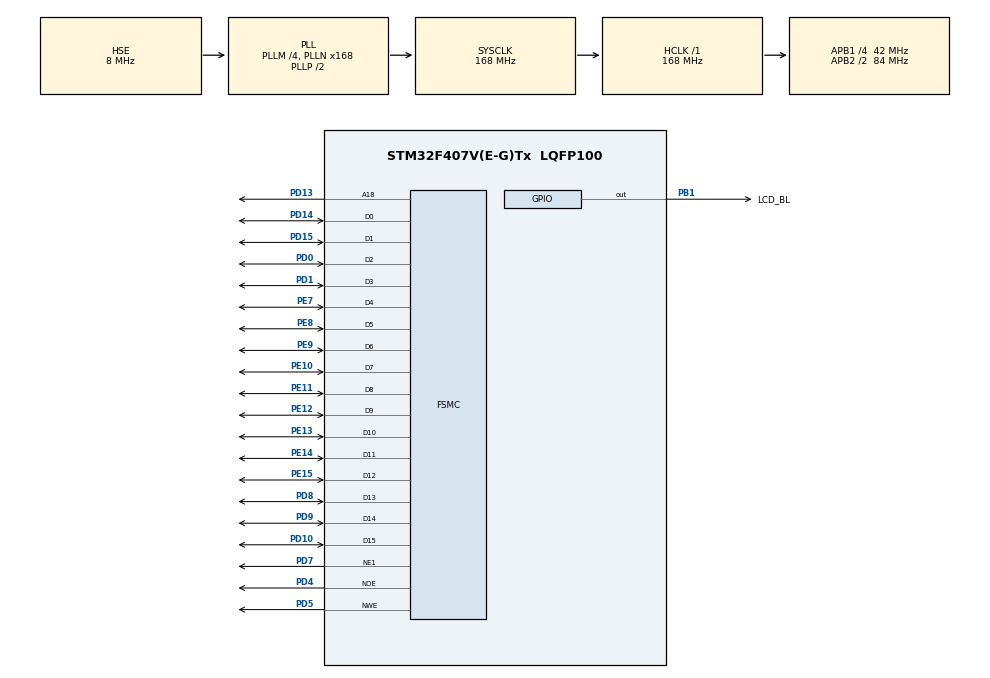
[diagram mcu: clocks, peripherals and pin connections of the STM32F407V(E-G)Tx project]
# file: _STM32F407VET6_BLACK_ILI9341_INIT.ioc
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FSMC.BusTurnAroundDuration1=0
FSMC.DataSetupTime1=60
FSMC.ExtendedAddressSetupTime1=9
FSMC.ExtendedBusTurnAroundDuration1=0
FSMC.ExtendedDataSetupTime1=8
FSMC.ExtendedMode1=FSMC_EXTENDED_MODE_ENABLE
Mcu.Family=STM32F4
Mcu.Name=STM32F407V(E-G)Tx
Mcu.Package=LQFP100
NVIC.PriorityGroup=NVIC_PRIORITYGROUP_4
PA13.Mode=Serial_Wire
PA13.Signal=SYS_JTMS-SWDIO
PA14.Mode=Serial_Wire
PA14.Signal=SYS_JTCK-SWCLK
PB1.GPIO_Label=LCD_BL
PB1.Signal=GPIO_Output
PD0.Mode=16b-d1
PD0.Signal=FSMC_D2
PD1.Mode=16b-d1
PD1.Signal=FSMC_D3
PD10.Mode=16b-d1
PD10.Signal=FSMC_D15
PD13.Mode=A18_1
PD13.Signal=FSMC_A18
PD14.Mode=16b-d1
PD14.Signal=FSMC_D0
PD15.Mode=16b-d1
PD15.Signal=FSMC_D1
PD4.Mode=Lcd1
PD4.Signal=FSMC_NOE
PD5.Mode=Lcd1
PD5.Signal=FSMC_NWE
PD7.Mode=NorPsramChipSelect1_1
PD7.Signal=FSMC_NE1
PD8.Mode=16b-d1
PD8.Signal=FSMC_D13
PD9.Mode=16b-d1
PD9.Signal=FSMC_D14
PE10.Mode=16b-d1
PE10.Signal=FSMC_D7
PE11.Mode=16b-d1
PE11.Signal=FSMC_D8
PE12.Mode=16b-d1
PE12.Signal=FSMC_D9
PE13.Mode=16b-d1
PE13.Signal=FSMC_D10
PE14.Mode=16b-d1
PE14.Signal=FSMC_D11
PE15.Mode=16b-d1
PE15.Signal=FSMC_D12
PE7.Mode=16b-d1
PE7.Signal=FSMC_D4
PE8.Mode=16b-d1
PE8.Signal=FSMC_D5
PE9.Mode=16b-d1
PE9.Signal=FSMC_D6
PH0-OSC_IN.Mode=HSE-External-Oscillator
PH0-OSC_IN.Signal=RCC_OSC_IN
PH1-OSC_OUT.Mode=HSE-External-Oscillator
PH1-OSC_OUT.Signal=RCC_OSC_OUT
ProjectManager.HeapSize=0x400
ProjectManager.StackSize=0x800
ProjectManager.TargetToolchain=STM32CubeIDE
RCC.48MHZClocksFreq_Value=48000000
RCC.AHBFreq_Value=168000000
RCC.APB1CLKDivider=RCC_HCLK_DIV4
RCC.APB1Freq_Value=42000000
RCC.APB1TimFreq_Value=84000000
RCC.APB2CLKDivider=RCC_HCLK_DIV2
RCC.APB2Freq_Value=84000000
RCC.APB2TimFreq_Value=168000000
RCC.CortexFreq_Value=168000000
RCC.HCLKFreq_Value=168000000
RCC.HSE_VALUE=8000000
RCC.HSI_VALUE=16000000
RCC.LSE_VALUE=32768
RCC.PLLM=4
RCC.PLLN=168
RCC.PLLQ=7
RCC.PLLSourceVirtual=RCC_PLLSOURCE_HSE
RCC.SYSCLKFreq_VALUE=168000000
RCC.SYSCLKSource=RCC_SYSCLKSOURCE_PLLCLK
RCC.VCOOutputFreq_Value=336000000
VP_CRC_VS_CRC.Mode=CRC_Activate
VP_RNG_VS_RNG.Mode=RNG_Activate
VP_TIM6_VS_ClockSourceINT.Mode=Enable_Timer
board=custom

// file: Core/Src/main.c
/* USER CODE BEGIN Header */
/**
  ******************************************************************************
  * @file           : main.c
  * @brief          : Main program body
  ******************************************************************************
  * @attention
  *
  * Copyright (c) 2023 STMicroelectronics.
  * All rights reserved.
  *
  * This software is licensed under terms that can be found in the LICENSE file
  * in the root directory of this software component.
  * If no LICENSE file comes with this software, it is provided AS-IS.
  *
  ******************************************************************************
  */
/* USER CODE END Header */
#include "main.h"

/* USER CODE BEGIN Includes */
#include "ili9341.h"
/* USER CODE END Includes */

CRC_HandleTypeDef hcrc;

RNG_HandleTypeDef hrng;

TIM_HandleTypeDef htim6;

SRAM_HandleTypeDef hsram1;

void SystemClock_Config(void);
static void MX_GPIO_Init(void);
static void MX_FSMC_Init(void);
static void MX_RNG_Init(void);
static void MX_TIM6_Init(void);
static void MX_CRC_Init(void);

int main(void)
{

  /* MCU Configuration--------------------------------------------------------*/

  /* Reset of all peripherals, Initializes the Flash interface and the Systick. */
  HAL_Init();

  /* Configure the system clock */
  SystemClock_Config();

  /* Initialize all configured peripherals */
  MX_GPIO_Init();
  MX_FSMC_Init();
  MX_RNG_Init();
  MX_TIM6_Init();
  MX_CRC_Init();
  /* USER CODE BEGIN 2 */

  LCD_ILI9341_init();

  /* USER CODE END 2 */

  /* Infinite loop */
  while (1)
  {

  }
}

void SystemClock_Config(void)
{
  RCC_OscInitTypeDef RCC_OscInitStruct = {0};
  RCC_ClkInitTypeDef RCC_ClkInitStruct = {0};

  /** Configure the main internal regulator output voltage
  */
  __HAL_RCC_PWR_CLK_ENABLE();
  __HAL_PWR_VOLTAGESCALING_CONFIG(PWR_REGULATOR_VOLTAGE_SCALE1);

  /** Initializes the RCC Oscillators according to the specified parameters
  * in the RCC_OscInitTypeDef structure.
  */
  RCC_OscInitStruct.OscillatorType = RCC_OSCILLATORTYPE_HSE;
  RCC_OscInitStruct.HSEState = RCC_HSE_ON;
  RCC_OscInitStruct.PLL.PLLState = RCC_PLL_ON;
  RCC_OscInitStruct.PLL.PLLSource = RCC_PLLSOURCE_HSE;
  RCC_OscInitStruct.PLL.PLLM = 4;
  RCC_OscInitStruct.PLL.PLLN = 168;
  RCC_OscInitStruct.PLL.PLLP = RCC_PLLP_DIV2;
  RCC_OscInitStruct.PLL.PLLQ = 7;
  if (HAL_RCC_OscConfig(&RCC_OscInitStruct) != HAL_OK)
  {
    Error_Handler();
  }

  /** Initializes the CPU, AHB and APB buses clocks
  */
  RCC_ClkInitStruct.ClockType = RCC_CLOCKTYPE_HCLK|RCC_CLOCKTYPE_SYSCLK
                              |RCC_CLOCKTYPE_PCLK1|RCC_CLOCKTYPE_PCLK2;
  RCC_ClkInitStruct.SYSCLKSource = RCC_SYSCLKSOURCE_PLLCLK;
  RCC_ClkInitStruct.AHBCLKDivider = RCC_SYSCLK_DIV1;
  RCC_ClkInitStruct.APB1CLKDivider = RCC_HCLK_DIV4;
  RCC_ClkInitStruct.APB2CLKDivider = RCC_HCLK_DIV2;

  if (HAL_RCC_ClockConfig(&RCC_ClkInitStruct, FLASH_LATENCY_5) != HAL_OK)
  {
    Error_Handler();
  }
}

static void MX_CRC_Init(void)
{

  hcrc.Instance = CRC;
  if (HAL_CRC_Init(&hcrc) != HAL_OK)
  {
    Error_Handler();
  }

}

static void MX_RNG_Init(void)
{

  hrng.Instance = RNG;
  if (HAL_RNG_Init(&hrng) != HAL_OK)
  {
    Error_Handler();
  }

}

static void MX_TIM6_Init(void)
{

  TIM_MasterConfigTypeDef sMasterConfig = {0};

  htim6.Instance = TIM6;
  htim6.Init.Prescaler = 0;
  htim6.Init.CounterMode = TIM_COUNTERMODE_UP;
  htim6.Init.Period = 65535;
  htim6.Init.AutoReloadPreload = TIM_AUTORELOAD_PRELOAD_DISABLE;
  if (HAL_TIM_Base_Init(&htim6) != HAL_OK)
  {
    Error_Handler();
  }
  sMasterConfig.MasterOutputTrigger = TIM_TRGO_RESET;
  sMasterConfig.MasterSlaveMode = TIM_MASTERSLAVEMODE_DISABLE;
  if (HAL_TIMEx_MasterConfigSynchronization(&htim6, &sMasterConfig) != HAL_OK)
  {
    Error_Handler();
  }

}

static void MX_GPIO_Init(void)
{
  GPIO_InitTypeDef GPIO_InitStruct = {0};

  /* GPIO Ports Clock Enable */
  __HAL_RCC_GPIOH_CLK_ENABLE();
  __HAL_RCC_GPIOB_CLK_ENABLE();
  __HAL_RCC_GPIOE_CLK_ENABLE();
  __HAL_RCC_GPIOD_CLK_ENABLE();
  __HAL_RCC_GPIOA_CLK_ENABLE();

  /*Configure GPIO pin Output Level */
  HAL_GPIO_WritePin(LCD_BL_GPIO_Port, LCD_BL_Pin, GPIO_PIN_RESET);

  /*Configure GPIO pin : LCD_BL_Pin */
  GPIO_InitStruct.Pin = LCD_BL_Pin;
  GPIO_InitStruct.Mode = GPIO_MODE_OUTPUT_PP;
  GPIO_InitStruct.Pull = GPIO_NOPULL;
  GPIO_InitStruct.Speed = GPIO_SPEED_FREQ_LOW;
  HAL_GPIO_Init(LCD_BL_GPIO_Port, &GPIO_InitStruct);

}

/* FSMC initialization function */
static void MX_FSMC_Init(void)
{

  FSMC_NORSRAM_TimingTypeDef Timing = {0};
  FSMC_NORSRAM_TimingTypeDef ExtTiming = {0};

  /** Perform the SRAM1 memory initialization sequence
  */
  hsram1.Instance = FSMC_NORSRAM_DEVICE;
  hsram1.Extended = FSMC_NORSRAM_EXTENDED_DEVICE;
  /* hsram1.Init */
  hsram1.Init.NSBank = FSMC_NORSRAM_BANK1;
  hsram1.Init.DataAddressMux = FSMC_DATA_ADDRESS_MUX_DISABLE;
  hsram1.Init.MemoryType = FSMC_MEMORY_TYPE_SRAM;
  hsram1.Init.MemoryDataWidth = FSMC_NORSRAM_MEM_BUS_WIDTH_16;
  hsram1.Init.BurstAccessMode = FSMC_BURST_ACCESS_MODE_DISABLE;
  hsram1.Init.WaitSignalPolarity = FSMC_WAIT_SIGNAL_POLARITY_LOW;
  hsram1.Init.WrapMode = FSMC_WRAP_MODE_DISABLE;
  hsram1.Init.WaitSignalActive = FSMC_WAIT_TIMING_BEFORE_WS;
  hsram1.Init.WriteOperation = FSMC_WRITE_OPERATION_ENABLE;
  hsram1.Init.WaitSignal = FSMC_WAIT_SIGNAL_DISABLE;
  hsram1.Init.ExtendedMode = FSMC_EXTENDED_MODE_ENABLE;
  hsram1.Init.AsynchronousWait = FSMC_ASYNCHRONOUS_WAIT_DISABLE;
  hsram1.Init.WriteBurst = FSMC_WRITE_BURST_DISABLE;
  hsram1.Init.PageSize = FSMC_PAGE_SIZE_NONE;
  /* Timing */
  Timing.AddressSetupTime = 15;
  Timing.AddressHoldTime = 15;
  Timing.DataSetupTime = 60;
  Timing.BusTurnAroundDuration = 0;
  Timing.CLKDivision = 16;
  Timing.DataLatency = 17;
  Timing.AccessMode = FSMC_ACCESS_MODE_A;
  /* ExtTiming */
  ExtTiming.AddressSetupTime = 9;
  ExtTiming.AddressHoldTime = 15;
  ExtTiming.DataSetupTime = 8;
  ExtTiming.BusTurnAroundDuration = 0;
  ExtTiming.CLKDivision = 16;
  ExtTiming.DataLatency = 17;
  ExtTiming.AccessMode = FSMC_ACCESS_MODE_A;

  if (HAL_SRAM_Init(&hsram1, &Timing, &ExtTiming) != HAL_OK)
  {
    Error_Handler( );
  }

}

void Error_Handler(void)
{
  __disable_irq();
  while (1)
  {
  }
}
